# HT32F1654 register map
Vendor: Holtek Semiconductor; Series: HT32F1xxx; File version: 1.0
CPU: CM3 r2p0, little endian, VTOR, 4 interrupt priority bits, 69 interrupts
Registers are 32-bit, read-write, reset 0x0 unless marked. A register's access mark holds for its fields unless they carry their own. Offsets are from the block's base; [hi:lo] are bit positions; {n}, {i} and the like mark numbered series.

## RTC
Base 0x4006A000
0x00 CNT
  [31:0] RTCCNT
0x04 CMP
  [31:0] RTCCMP
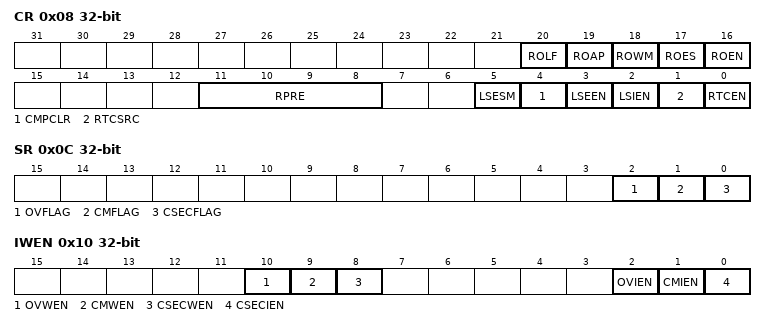
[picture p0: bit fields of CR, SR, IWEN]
0x08 CR
  [20] ROLF, [19] ROAP, [18] ROWM, [17] ROES, [16] ROEN, [11:8] RPRE, [5] LSESM, [4] CMPCLR, [3] LSEEN, [2] LSIEN, [1] RTCSRC, [0] RTCEN
0x0C SR
  [2] OVFLAG, [1] CMFLAG, [0] CSECFLAG
0x10 IWEN
  [10] OVWEN, [9] CMWEN, [8] CSECWEN, [2] OVIEN, [1] CMIEN, [0] CSECIEN

## WDT
Base 0x40068000
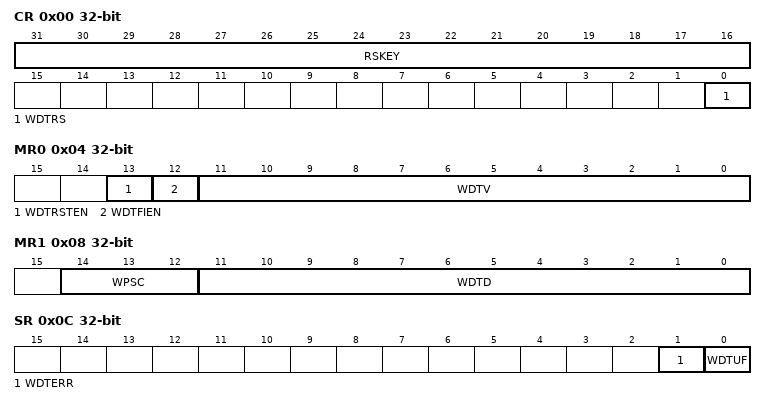
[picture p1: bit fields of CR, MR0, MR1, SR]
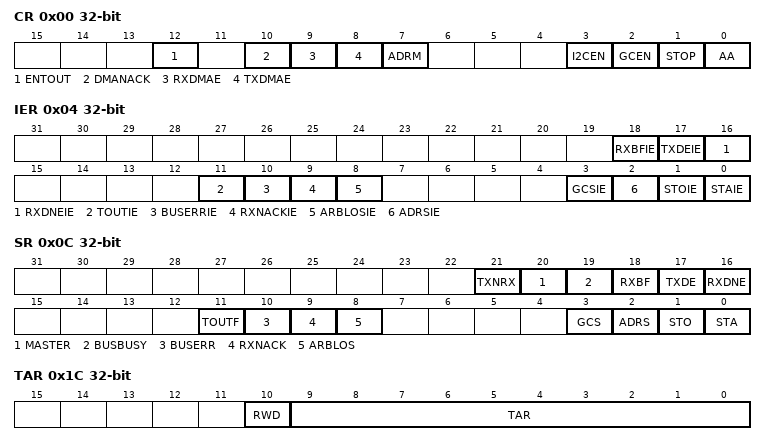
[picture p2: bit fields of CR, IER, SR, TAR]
0x00 CR
  [31:16] RSKEY, [0] WDTRS
0x04 MR0
  [13] WDTRSTEN, [12] WDTFIEN, [11:0] WDTV
0x08 MR1
  [14:12] WPSC, [11:0] WDTD
0x0C SR
  [1] WDTERR, [0] WDTUF
0x10 PR
  [15:0] PROTECT

## I2C0
Base 0x40048000
Same registers: I2C1 0x40049000
0x00 CR
  [12] ENTOUT, [10] DMANACK, [9] RXDMAE, [8] TXDMAE, [7] ADRM, [3] I2CEN, [2] GCEN, [1] STOP, [0] AA
0x04 IER
  [18] RXBFIE, [17] TXDEIE, [16] RXDNEIE, [11] TOUTIE, [10] BUSERRIE, [9] RXNACKIE, [8] ARBLOSIE, [3] GCSIE, [2] ADRSIE, [1] STOIE, [0] STAIE
0x08 ADDR
  [9:0] ADDR
0x0C SR
  [21] TXNRX, [20] MASTER, [19] BUSBUSY, [18] RXBF, [17] TXDE, [16] RXDNE, [11] TOUTF, [10] BUSERR, [9] RXNACK, [8] ARBLOS, [3] GCS, [2] ADRS, [1] STO, [0] STA
0x10 SHPGR
  [15:0] SHPG
0x14 SLPGR
  [15:0] SLPG
0x18 DR
  [7:0] DATA
0x1C TAR
  [10] RWD, [9:0] TAR
0x20 ADDMR
  [9:0] ADDMR
0x24 ADDSR
  [9:0] ADDSR
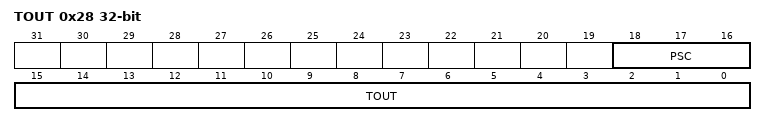
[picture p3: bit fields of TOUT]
0x28 TOUT
  [18:16] PSC, [15:0] TOUT

## SPI0
Base 0x40004000
Same registers: SPI1 0x40044000
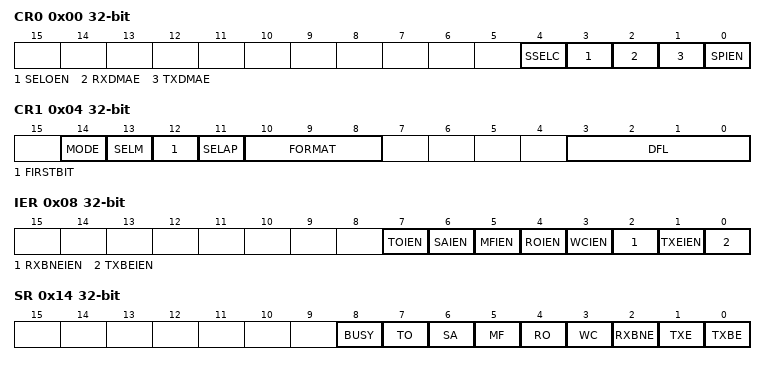
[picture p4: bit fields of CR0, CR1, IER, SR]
0x00 CR0
  [4] SSELC, [3] SELOEN, [2] RXDMAE, [1] TXDMAE, [0] SPIEN
0x04 CR1
  [14] MODE, [13] SELM, [12] FIRSTBIT, [11] SELAP, [10:8] FORMAT, [3:0] DFL
0x08 IER
  [7] TOIEN, [6] SAIEN, [5] MFIEN, [4] ROIEN, [3] WCIEN, [2] RXBNEIEN, [1] TXEIEN, [0] TXBEIEN
0x0C CPR
  [15:0] CP
0x10 DR
  [15:0] DR
0x14 SR
  [8] BUSY, [7] TO, [6] SA, [5] MF, [4] RO, [3] WC, [2] RXBNE, [1] TXE, [0] TXBE
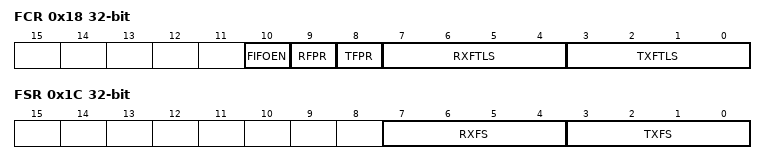
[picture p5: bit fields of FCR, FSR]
0x18 FCR
  [10] FIFOEN, [9] RFPR, [8] TFPR, [7:4] RXFTLS, [3:0] TXFTLS
0x1C FSR
  [7:4] RXFS, [3:0] TXFS
0x20 FTOCR
  [31:0] TOC

## USART0
Base 0x40000000
Same registers: USART1 0x40040000
0x00 RBR
  [8:0] RD
0x00 TBR (USART0 view)
  [8:0] TD
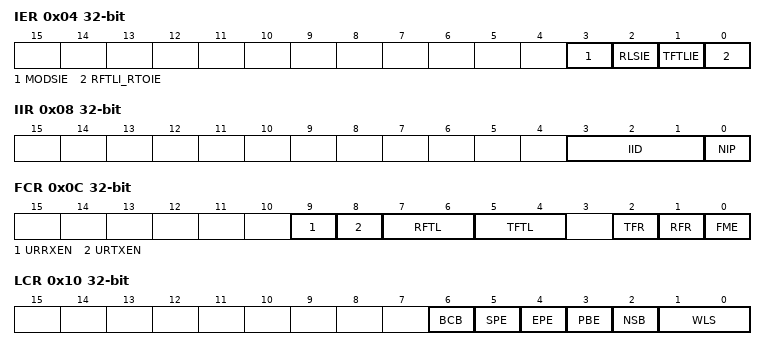
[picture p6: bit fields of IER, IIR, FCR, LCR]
0x04 IER
  [3] MODSIE, [2] RLSIE, [1] TFTLIE, [0] RFTLI_RTOIE
0x08 IIR
  [3:1] IID, [0] NIP
0x0C FCR
  [9] URRXEN, [8] URTXEN, [7:6] RFTL, [5:4] TFTL, [2] TFR, [1] RFR, [0] FME
0x10 LCR
  [6] BCB, [5] SPE, [4] EPE, [3] PBE, [2] NSB, [1:0] WLS
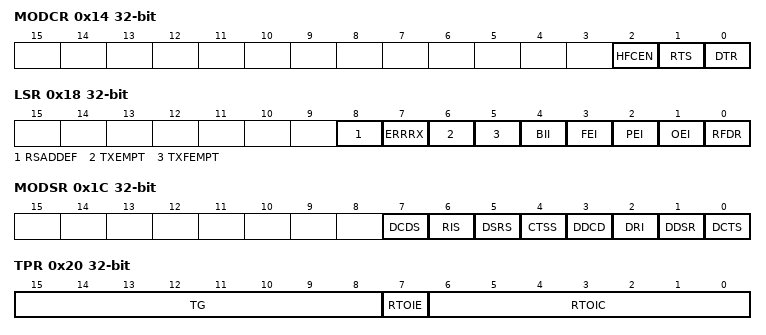
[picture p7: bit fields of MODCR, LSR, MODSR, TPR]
0x14 MODCR
  [2] HFCEN, [1] RTS, [0] DTR
0x18 LSR
  [8] RSADDEF, [7] ERRRX, [6] TXEMPT, [5] TXFEMPT, [4] BII, [3] FEI, [2] PEI, [1] OEI, [0] RFDR
0x1C MODSR
  [7] DCDS, [6] RIS, [5] DSRS, [4] CTSS, [3] DDCD, [2] DRI, [1] DDSR, [0] DCTS
0x20 TPR
  [15:8] TG, [7] RTOIE, [6:0] RTOIC
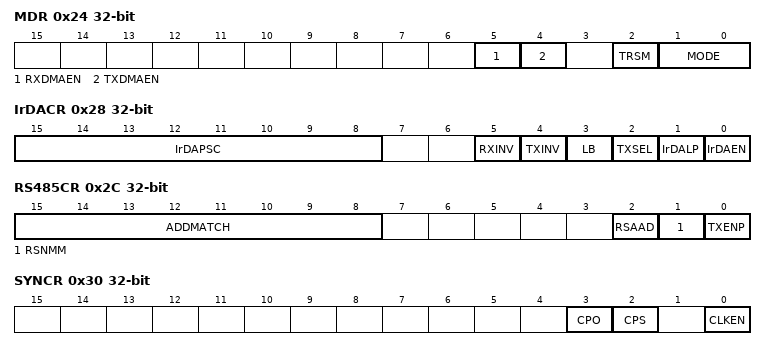
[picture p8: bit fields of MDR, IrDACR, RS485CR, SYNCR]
0x24 MDR
  [5] RXDMAEN, [4] TXDMAEN, [2] TRSM, [1:0] MODE
0x28 IrDACR
  [15:8] IrDAPSC, [5] RXINV, [4] TXINV, [3] LB, [2] TXSEL, [1] IrDALP, [0] IrDAEN
0x2C RS485CR
  [15:8] ADDMATCH, [2] RSAAD, [1] RSNMM, [0] TXENP
0x30 SYNCR
  [3] CPO, [2] CPS, [0] CLKEN
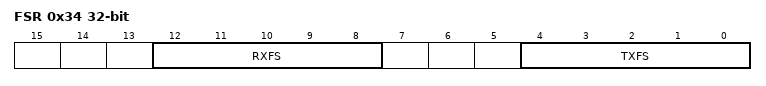
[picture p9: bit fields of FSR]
0x34 FSR
  [12:8] RXFS, [4:0] TXFS
0x38 DLR
  [15:0] BRD
0x40 DEGTSTR
  [1:0] LBM

## SCI
Base 0x40043000
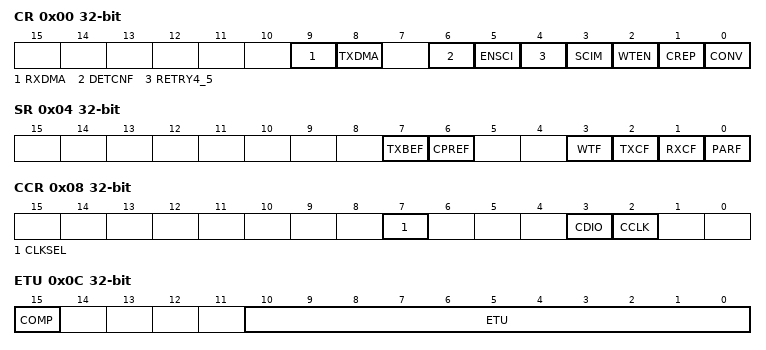
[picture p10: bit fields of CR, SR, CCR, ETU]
0x00 CR
  [9] RXDMA, [8] TXDMA, [6] DETCNF, [5] ENSCI, [4] RETRY4_5, [3] SCIM, [2] WTEN, [1] CREP, [0] CONV
0x04 SR
  [7] TXBEF, [6] CPREF, [3] WTF, [2] TXCF, [1] RXCF, [0] PARF
0x08 CCR
  [7] CLKSEL, [3] CDIO, [2] CCLK
0x0C ETU
  [15] COMP, [10:0] ETU
0x10 GT
  [8:0] GT
0x14 WT
  [23:0] WT
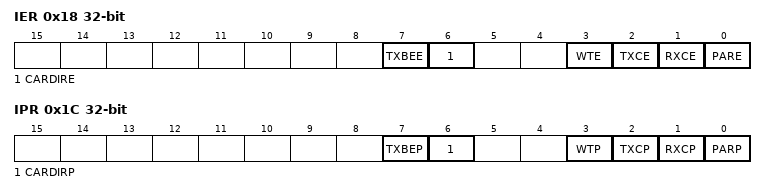
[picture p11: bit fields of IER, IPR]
0x18 IER
  [7] TXBEE, [6] CARDIRE, [3] WTE, [2] TXCE, [1] RXCE, [0] PARE
0x1C IPR
  [7] TXBEP, [6] CARDIRP, [3] WTP, [2] TXCP, [1] RXCP, [0] PARP
0x20 TXB
  [7:0] TB
0x24 RXB
  [7:0] RB
0x28 PSC
  [5:0] PSC

## USB
Base 0x400A8000
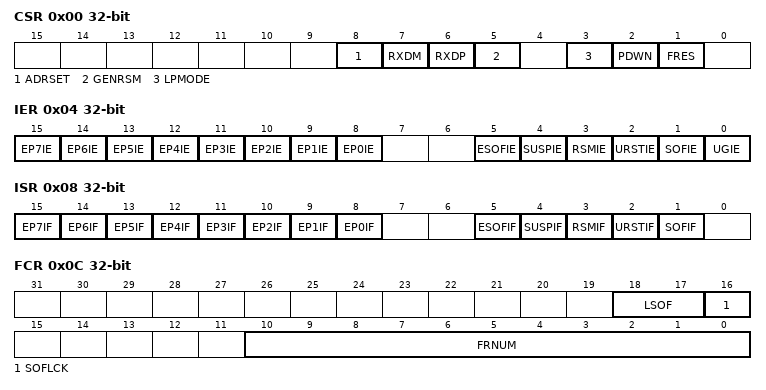
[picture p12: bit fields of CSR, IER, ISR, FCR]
0x00 CSR
  [8] ADRSET, [7] RXDM, [6] RXDP, [5] GENRSM, [3] LPMODE, [2] PDWN, [1] FRES
0x04 IER
  [n+8] EP{n}IE (n=0..7), [5] ESOFIE, [4] SUSPIE, [3] RSMIE, [2] URSTIE, [1] SOFIE, [0] UGIE
0x08 ISR
  [n+8] EP{n}IF (n=0..7), [5] ESOFIF, [4] SUSPIF, [3] RSMIF, [2] URSTIF, [1] SOFIF
0x0C FCR
  [18:17] LSOF, [16] SOFLCK, [10:0] FRNUM
0x10 DEVAR
  [6:0] DEVA
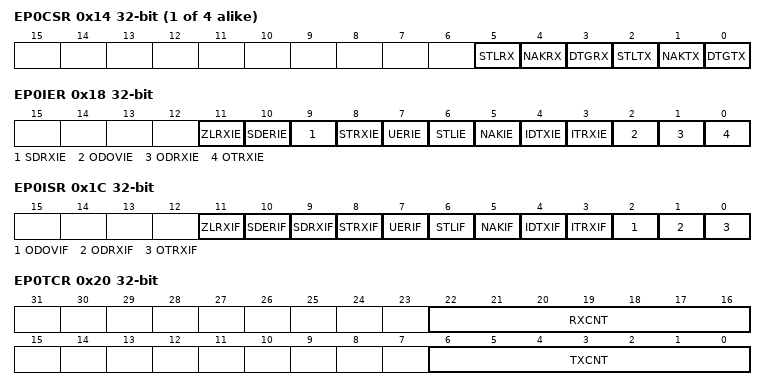
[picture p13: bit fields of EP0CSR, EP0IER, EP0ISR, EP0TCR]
{0x14+0x14*i} EP{i}CSR (i=0..3)
  [5] STLRX, [4] NAKRX, [3] DTGRX, [2] STLTX, [1] NAKTX, [0] DTGTX
0x18 EP0IER
  [11] ZLRXIE, [10] SDERIE, [9] SDRXIE, [8] STRXIE, [7] UERIE, [6] STLIE, [5] NAKIE, [4] IDTXIE, [3] ITRXIE, [2] ODOVIE, [1] ODRXIE, [0] OTRXIE
0x1C EP0ISR
  [11] ZLRXIF, [10] SDERIF, [9] SDRXIF, [8] STRXIF, [7] UERIF, [6] STLIF, [5] NAKIF, [4] IDTXIF, [3] ITRXIF, [2] ODOVIF, [1] ODRXIF, [0] OTRXIF
0x20 EP0TCR
  [22:16] RXCNT, [6:0] TXCNT
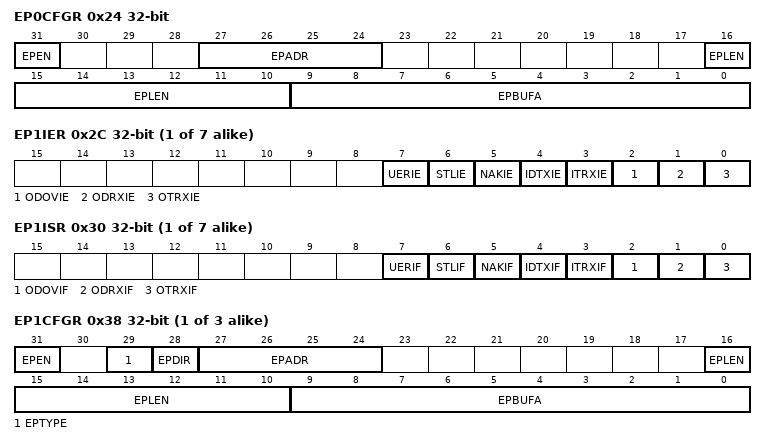
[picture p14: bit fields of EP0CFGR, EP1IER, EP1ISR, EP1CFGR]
0x24 EP0CFGR
  [31] EPEN, [27:24] EPADR, [16:10] EPLEN, [9:0] EPBUFA
{0x18+0x14*i} EP{i}IER (i=1..7)
  [7] UERIE, [6] STLIE, [5] NAKIE, [4] IDTXIE, [3] ITRXIE, [2] ODOVIE, [1] ODRXIE, [0] OTRXIE
{0x1C+0x14*i} EP{i}ISR (i=1..7)
  [7] UERIF, [6] STLIF, [5] NAKIF, [4] IDTXIF, [3] ITRXIF, [2] ODOVIF, [1] ODRXIF, [0] OTRXIF
{0x20+0x14*i} EP{i}TCR (i=1..3)
  [8:0] TCNT
{0x24+0x14*i} EP{i}CFGR (i=1..3)
  [31] EPEN, [29] EPTYPE, [28] EPDIR, [27:24] EPADR, [16:10] EPLEN, [9:0] EPBUFA
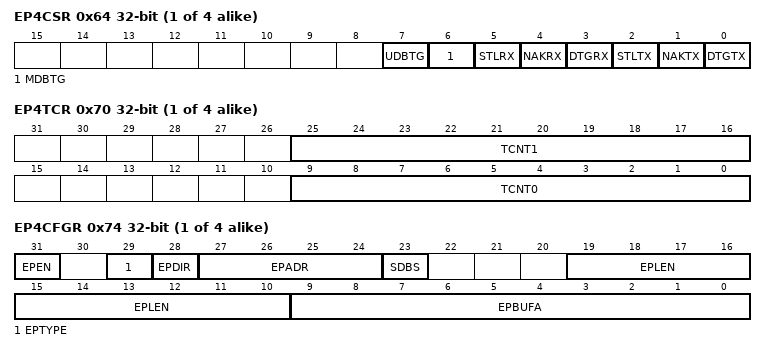
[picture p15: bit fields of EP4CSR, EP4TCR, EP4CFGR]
{0x14+0x14*i} EP{i}CSR (i=4..7)
  [7] UDBTG, [6] MDBTG, [5] STLRX, [4] NAKRX, [3] DTGRX, [2] STLTX, [1] NAKTX, [0] DTGTX
{0x20+0x14*i} EP{i}TCR (i=4..7)
  [25:16] TCNT1, [9:0] TCNT0
{0x24+0x14*i} EP{i}CFGR (i=4..7)
  [31] EPEN, [29] EPTYPE, [28] EPDIR, [27:24] EPADR, [23] SDBS, [19:10] EPLEN, [9:0] EPBUFA

## PDMA
Base 0x40090000
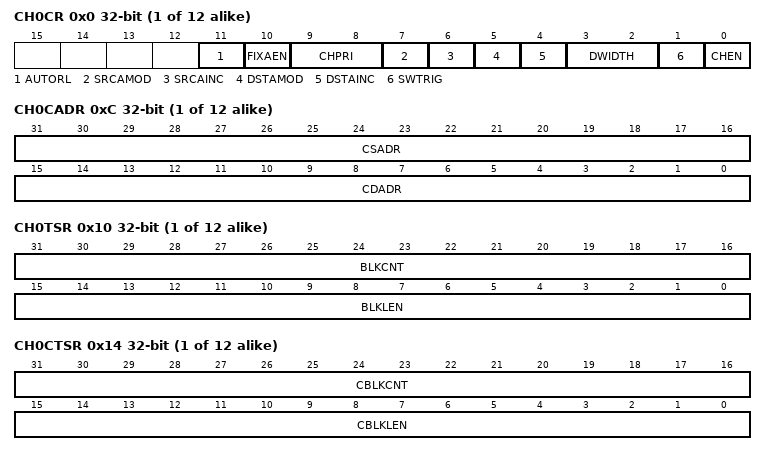
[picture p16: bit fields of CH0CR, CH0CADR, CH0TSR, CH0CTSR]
{0x0+0x18*i} CH{i}CR (i=0..11)
  [11] AUTORL, [10] FIXAEN, [9:8] CHPRI, [7] SRCAMOD, [6] SRCAINC, [5] DSTAMOD, [4] DSTAINC, [3:2] DWIDTH, [1] SWTRIG, [0] CHEN
{0x4+0x18*i} CH{i}SADR (i=0..11)
  [31:0] SADR
{0x8+0x18*i} CH{i}DADR (i=0..11)
  [31:0] DADR
{0xC+0x18*i} CH{i}CADR (i=0..11)
  [31:16] CSADR, [15:0] CDADR
{0x10+0x18*i} CH{i}TSR (i=0..11)
  [31:16] BLKCNT, [15:0] BLKLEN
{0x14+0x18*i} CH{i}CTSR (i=0..11)
  [31:16] CBLKCNT, [15:0] CBLKLEN
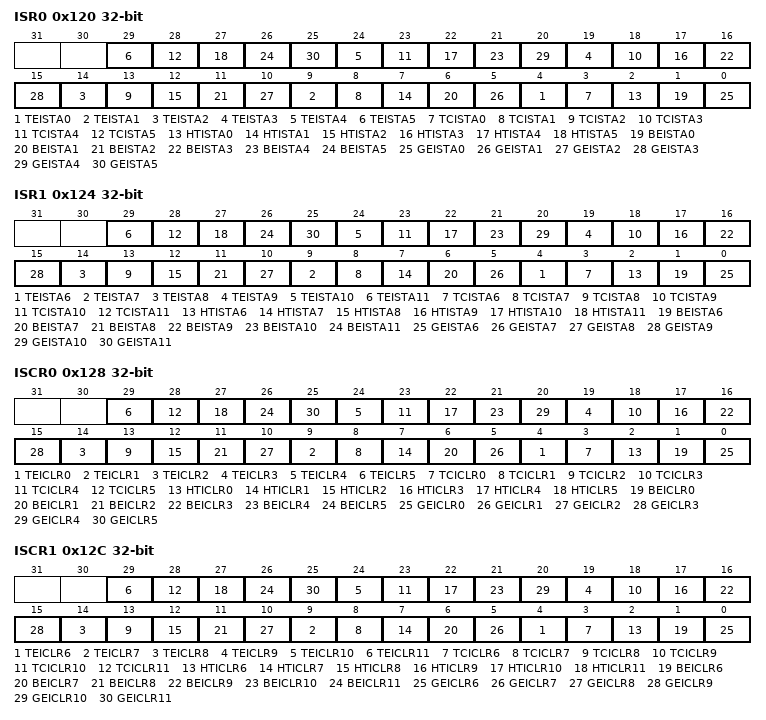
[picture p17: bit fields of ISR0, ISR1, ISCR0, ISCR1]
0x120 ISR0
  [5n+4] TEISTA{n} (n=0..5), [5n+3] TCISTA{n} (n=0..5), [5n+2] HTISTA{n} (n=0..5), [5n+1] BEISTA{n} (n=0..5), [5n] GEISTA{n} (n=0..5)
0x124 ISR1
  [5n-26] TEISTA{n} (n=6..11), [5n-27] TCISTA{n} (n=6..11), [5n-28] HTISTA{n} (n=6..11), [5n-29] BEISTA{n} (n=6..11), [5n-30] GEISTA{n} (n=6..11)
0x128 ISCR0
  [5n+4] TEICLR{n} (n=0..5), [5n+3] TCICLR{n} (n=0..5), [5n+2] HTICLR{n} (n=0..5), [5n+1] BEICLR{n} (n=0..5), [5n] GEICLR{n} (n=0..5)
0x12C ISCR1
  [5n-26] TEICLR{n} (n=6..11), [5n-27] TCICLR{n} (n=6..11), [5n-28] HTICLR{n} (n=6..11), [5n-29] BEICLR{n} (n=6..11), [5n-30] GEICLR{n} (n=6..11)
0x130 IER0
  [5n+4] TEIE{n} (n=0..5), [5n+3] TCIE{n} (n=0..5), [5n+2] HTIE{n} (n=0..5), [5n+1] BEIE{n} (n=0..5), [5n] GEIE{n} (n=0..5)
0x134 IER1
  [5n-26] TEIE{n} (n=6..11), [5n-27] TCIE{n} (n=6..11), [5n-28] HTIE{n} (n=6..11), [5n-29] BEIE{n} (n=6..11), [5n-30] GEIE{n} (n=6..11)
